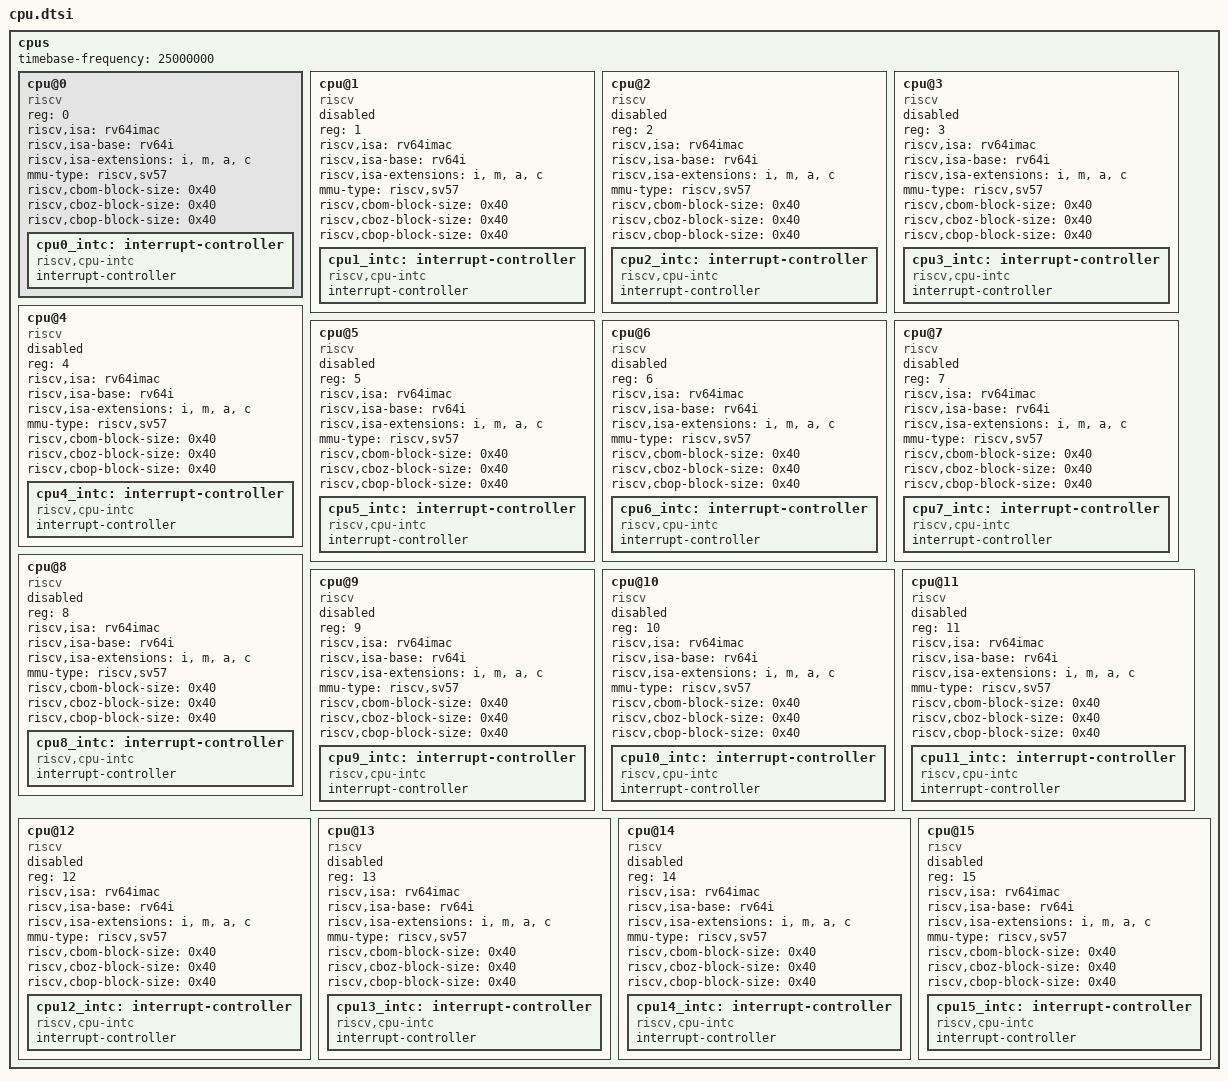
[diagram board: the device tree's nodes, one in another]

	cpus: cpus {
		#address-cells = <1>;
		#size-cells = <0>;
		timebase-frequency = <25000000>;

		cpu@0 {
			device_type = "cpu";
			reg = <0>;
			status = "okay";
			compatible = "riscv";
			riscv,isa = "rv64imac";
			riscv,isa-base = "rv64i";
			riscv,isa-extensions = "i", "m", "a", "c";
			mmu-type = "riscv,sv57";
			riscv,cbom-block-size = <0x40>;
			riscv,cboz-block-size = <0x40>;
			riscv,cbop-block-size = <0x40>;
			cpu0_intc: interrupt-controller {
				#interrupt-cells = <1>;
				compatible = "riscv,cpu-intc";
				interrupt-controller;
			};
		};
		cpu@1 {
			device_type = "cpu";
			reg = <1>;
			status = "skip";
			compatible = "riscv";
			riscv,isa = "rv64imac";
			riscv,isa-base = "rv64i";
			riscv,isa-extensions = "i", "m", "a", "c";
			mmu-type = "riscv,sv57";
			riscv,cbom-block-size = <0x40>;
			riscv,cboz-block-size = <0x40>;
			riscv,cbop-block-size = <0x40>;
			cpu1_intc: interrupt-controller {
				#interrupt-cells = <1>;
				compatible = "riscv,cpu-intc";
				interrupt-controller;
			};
		};
		cpu@2 {
			device_type = "cpu";
			reg = <2>;
			status = "skip";
			compatible = "riscv";
			riscv,isa = "rv64imac";
			riscv,isa-base = "rv64i";
			riscv,isa-extensions = "i", "m", "a", "c";
			mmu-type = "riscv,sv57";
			riscv,cbom-block-size = <0x40>;
			riscv,cboz-block-size = <0x40>;
			riscv,cbop-block-size = <0x40>;
			cpu2_intc: interrupt-controller {
				#interrupt-cells = <1>;
				compatible = "riscv,cpu-intc";
				interrupt-controller;
			};
		};
		cpu@3 {
			device_type = "cpu";
			reg = <3>;
			status = "skip";
			compatible = "riscv";
			riscv,isa = "rv64imac";
			riscv,isa-base = "rv64i";
			riscv,isa-extensions = "i", "m", "a", "c";
			mmu-type = "riscv,sv57";
			riscv,cbom-block-size = <0x40>;
			riscv,cboz-block-size = <0x40>;
			riscv,cbop-block-size = <0x40>;
			cpu3_intc: interrupt-controller {
				#interrupt-cells = <1>;
				compatible = "riscv,cpu-intc";
				interrupt-controller;
			};
		};
		cpu@4 {
			device_type = "cpu";
			reg = <4>;
			status = "skip";
			compatible = "riscv";
			riscv,isa = "rv64imac";
			riscv,isa-base = "rv64i";
			riscv,isa-extensions = "i", "m", "a", "c";
			mmu-type = "riscv,sv57";
			riscv,cbom-block-size = <0x40>;
			riscv,cboz-block-size = <0x40>;
			riscv,cbop-block-size = <0x40>;
			cpu4_intc: interrupt-controller {
				#interrupt-cells = <1>;
				compatible = "riscv,cpu-intc";
				interrupt-controller;
			};
		};
		cpu@5 {
			device_type = "cpu";
			reg = <5>;
			status = "skip";
			compatible = "riscv";
			riscv,isa = "rv64imac";
			riscv,isa-base = "rv64i";
			riscv,isa-extensions = "i", "m", "a", "c";
			mmu-type = "riscv,sv57";
			riscv,cbom-block-size = <0x40>;
			riscv,cboz-block-size = <0x40>;
			riscv,cbop-block-size = <0x40>;
			cpu5_intc: interrupt-controller {
				#interrupt-cells = <1>;
				compatible = "riscv,cpu-intc";
				interrupt-controller;
			};
		};
		cpu@6 {
			device_type = "cpu";
			reg = <6>;
			status = "skip";
			compatible = "riscv";
			riscv,isa = "rv64imac";
			riscv,isa-base = "rv64i";
			riscv,isa-extensions = "i", "m", "a", "c";
			mmu-type = "riscv,sv57";
			riscv,cbom-block-size = <0x40>;
			riscv,cboz-block-size = <0x40>;
			riscv,cbop-block-size = <0x40>;
			cpu6_intc: interrupt-controller {
				#interrupt-cells = <1>;
				compatible = "riscv,cpu-intc";
				interrupt-controller;
			};
		};
		cpu@7 {
			device_type = "cpu";
			reg = <7>;
			status = "skip";
			compatible = "riscv";
			riscv,isa = "rv64imac";
			riscv,isa-base = "rv64i";
			riscv,isa-extensions = "i", "m", "a", "c";
			mmu-type = "riscv,sv57";
			riscv,cbom-block-size = <0x40>;
			riscv,cboz-block-size = <0x40>;
			riscv,cbop-block-size = <0x40>;
			cpu7_intc: interrupt-controller {
				#interrupt-cells = <1>;
				compatible = "riscv,cpu-intc";
				interrupt-controller;
			};
		};
		cpu@8 {
			device_type = "cpu";
			reg = <8>;
			status = "skip";
			compatible = "riscv";
			riscv,isa = "rv64imac";
			riscv,isa-base = "rv64i";
			riscv,isa-extensions = "i", "m", "a", "c";
			mmu-type = "riscv,sv57";
			riscv,cbom-block-size = <0x40>;
			riscv,cboz-block-size = <0x40>;
			riscv,cbop-block-size = <0x40>;
			cpu8_intc: interrupt-controller {
				#interrupt-cells = <1>;
				compatible = "riscv,cpu-intc";
				interrupt-controller;
			};
		};
		cpu@9 {
			device_type = "cpu";
			reg = <9>;
			status = "skip";
			compatible = "riscv";
			riscv,isa = "rv64imac";
			riscv,isa-base = "rv64i";
			riscv,isa-extensions = "i", "m", "a", "c";
			mmu-type = "riscv,sv57";
			riscv,cbom-block-size = <0x40>;
			riscv,cboz-block-size = <0x40>;
			riscv,cbop-block-size = <0x40>;
			cpu9_intc: interrupt-controller {
				#interrupt-cells = <1>;
				compatible = "riscv,cpu-intc";
				interrupt-controller;
			};
		};
		cpu@10 {
			device_type = "cpu";
			reg = <10>;
			status = "skip";
			compatible = "riscv";
			riscv,isa = "rv64imac";
			riscv,isa-base = "rv64i";
			riscv,isa-extensions = "i", "m", "a", "c";
			mmu-type = "riscv,sv57";
			riscv,cbom-block-size = <0x40>;
			riscv,cboz-block-size = <0x40>;
			riscv,cbop-block-size = <0x40>;
			cpu10_intc: interrupt-controller {
				#interrupt-cells = <1>;
				compatible = "riscv,cpu-intc";
				interrupt-controller;
			};
		};
		cpu@11 {
			device_type = "cpu";
			reg = <11>;
			status = "skip";
			compatible = "riscv";
			riscv,isa = "rv64imac";
			riscv,isa-base = "rv64i";
			riscv,isa-extensions = "i", "m", "a", "c";
			mmu-type = "riscv,sv57";
			riscv,cbom-block-size = <0x40>;
			riscv,cboz-block-size = <0x40>;
			riscv,cbop-block-size = <0x40>;
			cpu11_intc: interrupt-controller {
				#interrupt-cells = <1>;
				compatible = "riscv,cpu-intc";
				interrupt-controller;
			};
		};
		cpu@12 {
			device_type = "cpu";
			reg = <12>;
			status = "skip";
			compatible = "riscv";
			riscv,isa = "rv64imac";
			riscv,isa-base = "rv64i";
			riscv,isa-extensions = "i", "m", "a", "c";
			mmu-type = "riscv,sv57";
			riscv,cbom-block-size = <0x40>;
			riscv,cboz-block-size = <0x40>;
			riscv,cbop-block-size = <0x40>;
			cpu12_intc: interrupt-controller {
				#interrupt-cells = <1>;
				compatible = "riscv,cpu-intc";
				interrupt-controller;
			};
		};
		cpu@13 {
			device_type = "cpu";
			reg = <13>;
			status = "skip";
			compatible = "riscv";
			riscv,isa = "rv64imac";
			riscv,isa-base = "rv64i";
			riscv,isa-extensions = "i", "m", "a", "c";
			mmu-type = "riscv,sv57";
			riscv,cbom-block-size = <0x40>;
			riscv,cboz-block-size = <0x40>;
			riscv,cbop-block-size = <0x40>;
			cpu13_intc: interrupt-controller {
				#interrupt-cells = <1>;
				compatible = "riscv,cpu-intc";
				interrupt-controller;
			};
		};
		cpu@14 {
			device_type = "cpu";
			reg = <14>;
			status = "skip";
			compatible = "riscv";
			riscv,isa = "rv64imac";
			riscv,isa-base = "rv64i";
			riscv,isa-extensions = "i", "m", "a", "c";
			mmu-type = "riscv,sv57";
			riscv,cbom-block-size = <0x40>;
			riscv,cboz-block-size = <0x40>;
			riscv,cbop-block-size = <0x40>;
			cpu14_intc: interrupt-controller {
				#interrupt-cells = <1>;
				compatible = "riscv,cpu-intc";
				interrupt-controller;
			};
		};
		cpu@15 {
			device_type = "cpu";
			reg = <15>;
			status = "skip";
			compatible = "riscv";
			riscv,isa = "rv64imac";
			riscv,isa-base = "rv64i";
			riscv,isa-extensions = "i", "m", "a", "c";
			mmu-type = "riscv,sv57";
			riscv,cbom-block-size = <0x40>;
			riscv,cboz-block-size = <0x40>;
			riscv,cbop-block-size = <0x40>;
			cpu15_intc: interrupt-controller {
				#interrupt-cells = <1>;
				compatible = "riscv,cpu-intc";
				interrupt-controller;
			};
		};
	};


